# SCR_TC3xx register map
Vendor: Infineon; File version: 1.0
Registers are 8-bit, read-write, reset 0x0 unless marked. A register's access mark holds for its fields unless they carry their own. Offsets are from the block's base; [hi:lo] are bit positions; {n}, {i} and the like mark numbered series.

## SCR_RTC — SCR Real-time clock
Base 0x00040000
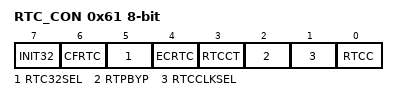
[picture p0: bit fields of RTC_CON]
0x61 RTC_CON — Real-Time Clock Control Register (SFR 0xE1, RMAP 0)
  [7] INIT32 — RTC32SEL Protection Bit. INIT32 is the protection bit for bit RTC_CON.RTC32SEL. To write RTC32SEL, INIT32 needs to be set. INIT32 has to be cleared after setting RTC32SEL. [rw]
    0=RTC32SEL_NOT_WRITABLE; 1=RTC32SEL_IS_WRITABLE
  [6] CFRTC — Real-Time Clock Compare Flag. This bit is set by hardware when there is a compare match, and can only be cleared by software. A wake-up request is generated only if the SCR is in standby mode. Writing 0 clears CFRTC. Writing 1 has no effect. [rwh]
  [5] RTC32SEL — External Oscillator Selection (32 kHz / 32.768 kHz). Note:Real-Time clock must be in stop operation before the clock setting can be changed. RTC32SEL selects the external clock input. This clock input is on pin SCR_P01.2 (P33.10), and can be 32.768 kHz or 32 kHz . This bit is write protected by bit INIT32 in this register. Before writing to RTC32SEL, INIT32 has to be set. INIT32 has to be cleared after setting RTC32SEL. [rw]
    0=EXTERNAL_CLOCK_OSCILLATOR_INPUT (External clock oscillator input is not selected; internal clock as configured by RTCCLKSEL is selected); 1=EXTERNAL_CLOCK_OSCILLATOR_INPUT_2 (External clock oscillator input is selected for the RTC)
  [4] ECRTC — Real-Time Clock Compare Interrupt Enable. [rw]
    0=DISABLE_REAL_TIME_CLOCK_COMPARE (Disable Real-Time clock compare interrupt); 1=ENABLE_REAL_TIME_CLOCK_COMPARE (Enable Real-Time clock compare interrupt)
  [3] RTCCT — Real-Time Clock Capture Event Trigger. When set, this bit is held until the capture occurs, and then cleared by hardware. Software has to poll this bit until it is cleared to ensure that the capture has occured. [rwh]
    0=NO_ACTION; 1=CAPTURE_EVENT_IS_TRIGGERED
  [2] RTPBYP — Real-Time Clock 9-bit Prescaler Bypass. Note:Real-Time clock must be in stop operation before the clock setting can be changed. [rw]
    0=V9_BIT_PRESCALER_IS_NOT_BYPASSED (9-bit prescaler is not bypassed); 1=V9_BIT_PRESCALER_IS_BYPASSED (9-bit prescaler is bypassed)
  [1] RTCCLKSEL — Real-Time Clock Input Clock Selection. Note:Real-Time clock must be in stop operation before the clock setting can be changed. Note:RTCCLKSEL must be cleared to 0 when the SCR is in standby mode and PCLK is 70 kHz, otherwise, the RTC counting will be disabled. [rw]
    0=V70_KHZ_CLOCK_IS_SELECTED (70 kHz clock is selected); 1=PCLK_CLOCK_IS_SELECTED
  [0] RTCC — Real-Time Clock Start/Stop Control. This bit enables or disables the RTC. After software writes to this bit, it takes 6 RTC Clock cycles for the RTC to be actually enabled or disabled. [rw]
    0=STOP_REAL_TIME_CLOCK_OPERATION; 1=START_REAL_TIME_CLOCK_OPERATION
{0x62+i} RTC_CNT{i} (i=0..3) — Count Clock Register {i} (SFR {0xE2+i}, RMAP 0)
  [7:0] CNT_VAL — Real-Time Clock Count Value. These bits represent the current 32-bit real-time clock value. The assignment is as follows: •RTC_CR3: Bits [31:24] •RTC_CR2: Bits [23:16] •RTC_CR1: Bits [15:8] •RTC_CR0: Bits [7:0] [rwh]
{0x66+i} RTC_CR{i} (i=0..3) — Real-Time Clock Compare/Capture Register {i} (SFR {0xE6+i}, RMAP 0)
  [7:0] CC_VAL — Compare/Capture Value. These bits represent the 32-bit compare/capture value. The assignment is as follows: •RTC_CR3: Bits [31:24] •RTC_CR2: Bits [23:16] •RTC_CR1: Bits [15:8] •RTC_CR0: Bits [7:0] [rwh]

## SCR_ADCOMP — SCR ADC comparator unit
Base 0x00047100
0x7A ADCOMP_RES ro reset 0xF0 — ADCOMP Result Register (SFR 0xFA, SCU_PAGE page 0, RMAP 0)
  [7:0] ADRES — ADC Conversion Result. This register shows the current converted ADC result. Software should ensure that the result is read before starting the next conversion. VIN = [LSB * (ADCRES-1)] ; LSB = 23.077 mV. Full Range : 5861.54 mV. For results of VIN =< 1, VIN is set to 0 V. Otherwise, VIN = [LSB * (ADCRES-1)]. [rh]
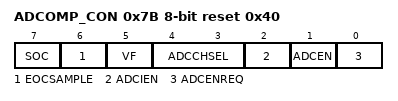
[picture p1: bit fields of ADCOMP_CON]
0x7B ADCOMP_CON reset 0x40 — ADCOMP Control Register (SFR 0xFB, SCU_PAGE page 0, RMAP 0)
  [7] SOC — ADC Start of Conversion Request. This bit activates a new conversion. Setting this bit has effect only when both, ADCEN and EOC, are set. This bit is automatically cleared by hardware once the conversion has started. If VF is set, setting SOC to 1 clears VF. [rwh]
    0=ADC_CONVERSION_IS_NOT_STARTED; 1=ADC_CONVERSION_IS_STARTED
  [6] EOCSAMPLE ro — ADC End of Conversion / Sampling Indication. This bit indicates that a conversion is completed and the result can be read. A new conversion via SOC can be started only when the EOC from the previous conversion has been set. This bit is automatically cleared when SOC is set. [rh]
    0=ADC_CONVERSION_IS_CURRENTLY_GOING (ADC conversion is currently going on); 1=ADC_CONVERSION_IS_COMPLETED_ADC (ADC conversion is completed. ADC is currently sampling.)
  [5] VF ro — ADC Valid Flag for Result Register. Indicates a new result in ADCOMP_RES register. [rh]
    0=THERE_IS_NO_VALID_RESULT; 1=A_NEW_RESULT_IS_AVAILABLE_IN_THE (A new result is available in the ADCOMP_RES result register. The valid flag is automatically cleared when bit SOC is set.)
  [4:3] ADCCHSEL — ADC Channel Select. This bitfield selects the channel and configures the 4:1 ADC multiplexer before a conversion is triggered. After a channel is selected, adequate time needs to be provided for sampling before a conversion is started. [rw]
    {v}=CH{v} (CH{v} is selected) (v=0..3)
  [2] ADCIEN — ADC Comparator Interrupt Enable. Software can read this bit to get the status whether the interrupt is currently enabled or disabled. [rw]
    0=NO_INTERRUPT_IS_GENERATED; 1=INTERRUPT_IS_GENERATED_AFTER (Interrupt is generated after conversion)
  [1] ADCEN ro — ADC Comparator Enable Status. This bit indicates that the ADC unit, the associated bandgap, and the clock required for the ADC unit are active, and a subsequent conversion can be triggered. It is set after some time after ADCOMP_CON.ANCENREQ is set. [rh]
    0=ADCOMP_UNIT_IS_DISABLED; 1=ADCOMP_UNIT_IS_ENABLED
  [0] ADCENREQ — ADC Comparator Enable Request. This bit activates the ADC unit, the associated bandgap and clock required for the ADC unit. It is required to wait some time for the units to start after the request. In case ADCENREQ is cleared during ongoing conversion, then the ADC is disabled when the currently running conversion is ended. [rw]
    0=ADCOMP_UNIT_IS_DISABLED; 1=ADCOMP_UNIT_IS_ENABLED
